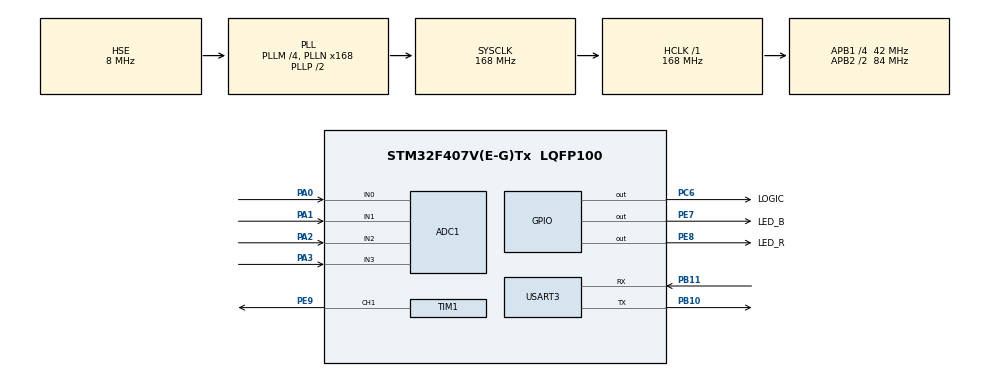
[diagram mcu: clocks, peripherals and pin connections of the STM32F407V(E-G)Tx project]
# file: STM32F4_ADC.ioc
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ADC1.Channel-0\#ChannelRegularConversion=ADC_CHANNEL_0
ADC1.ContinuousConvMode=ENABLE
ADC1.DMAContinuousRequests=ENABLE
ADC1.NbrOfConversionFlag=1
ADC1.Rank-0\#ChannelRegularConversion=1
ADC1.SamplingTime-0\#ChannelRegularConversion=ADC_SAMPLETIME_3CYCLES
ADC1.ScanConvMode=DISABLE
ADC1.master=1
Dma.ADC1.0.Direction=DMA_PERIPH_TO_MEMORY
Dma.ADC1.0.FIFOMode=DMA_FIFOMODE_DISABLE
Dma.ADC1.0.Instance=DMA2_Stream0
Dma.ADC1.0.MemDataAlignment=DMA_MDATAALIGN_HALFWORD
Dma.ADC1.0.MemInc=DMA_MINC_ENABLE
Dma.ADC1.0.Mode=DMA_NORMAL
Dma.ADC1.0.PeriphDataAlignment=DMA_PDATAALIGN_HALFWORD
Dma.ADC1.0.PeriphInc=DMA_PINC_DISABLE
Dma.ADC1.0.Priority=DMA_PRIORITY_HIGH
Dma.Request0=ADC1
Mcu.Family=STM32F4
Mcu.Name=STM32F407V(E-G)Tx
Mcu.Package=LQFP100
NVIC.ADC_IRQn=true\:0\:0\:false\:false\:true\:true\:true\:true
NVIC.DMA2_Stream0_IRQn=true\:0\:0\:false\:false\:true\:false\:true\:true
NVIC.PriorityGroup=NVIC_PRIORITYGROUP_4
PA0-WKUP.Signal=ADCx_IN0
PA1.Signal=ADCx_IN1
PA13.Mode=Serial_Wire
PA13.Signal=SYS_JTMS-SWDIO
PA14.Mode=Serial_Wire
PA14.Signal=SYS_JTCK-SWCLK
PA2.Signal=ADCx_IN2
PA3.Signal=ADCx_IN3
PB10.Mode=Asynchronous
PB10.Signal=USART3_TX
PB11.Mode=Asynchronous
PB11.Signal=USART3_RX
PC14-OSC32_IN.Mode=LSE-External-Oscillator
PC14-OSC32_IN.Signal=RCC_OSC32_IN
PC15-OSC32_OUT.Mode=LSE-External-Oscillator
PC15-OSC32_OUT.Signal=RCC_OSC32_OUT
PC6.GPIO_Label=LOGIC
PC6.GPIO_PuPd=GPIO_PULLUP
PC6.GPIO_Speed=GPIO_SPEED_FREQ_VERY_HIGH
PC6.Signal=GPIO_Output
PE7.GPIO_Label=LED_B
PE7.GPIO_ModeDefaultOutputPP=GPIO_MODE_OUTPUT_PP
PE7.GPIO_Speed=GPIO_SPEED_FREQ_MEDIUM
PE7.PinState=GPIO_PIN_RESET
PE7.Signal=GPIO_Output
PE8.GPIO_Label=LED_R
PE8.GPIO_ModeDefaultOutputPP=GPIO_MODE_OUTPUT_PP
PE8.GPIO_Speed=GPIO_SPEED_FREQ_MEDIUM
PE8.PinState=GPIO_PIN_RESET
PE8.Signal=GPIO_Output
PE9.Signal=S_TIM1_CH1
PH0-OSC_IN.Mode=HSE-External-Oscillator
PH0-OSC_IN.Signal=RCC_OSC_IN
PH1-OSC_OUT.Mode=HSE-External-Oscillator
PH1-OSC_OUT.Signal=RCC_OSC_OUT
ProjectManager.HeapSize=0x200
ProjectManager.StackSize=0x400
ProjectManager.TargetToolchain=MDK-ARM V5.32
RCC.48MHZClocksFreq_Value=84000000
RCC.AHBFreq_Value=168000000
RCC.APB1CLKDivider=RCC_HCLK_DIV4
RCC.APB1Freq_Value=42000000
RCC.APB1TimFreq_Value=84000000
RCC.APB2CLKDivider=RCC_HCLK_DIV2
RCC.APB2Freq_Value=84000000
RCC.APB2TimFreq_Value=168000000
RCC.CortexFreq_Value=168000000
RCC.HCLKFreq_Value=168000000
RCC.HSE_VALUE=8000000
RCC.HSI_VALUE=16000000
RCC.PLLM=4
RCC.PLLN=168
RCC.PLLSourceVirtual=RCC_PLLSOURCE_HSE
RCC.SYSCLKFreq_VALUE=168000000
RCC.SYSCLKSource=RCC_SYSCLKSOURCE_PLLCLK
RCC.VCOOutputFreq_Value=336000000
SH.ADCx_IN0.0=ADC1_IN0,IN0
SH.ADCx_IN1.0=ADC1_IN1,IN1
SH.ADCx_IN2.0=ADC1_IN2,IN2
SH.ADCx_IN3.0=ADC1_IN3,IN3
SH.S_TIM1_CH1.0=TIM1_CH1,PWM Generation1 CH1
TIM1.Channel-PWM\ Generation1\ CH1=TIM_CHANNEL_1
TIM1.Period=100
TIM1.Prescaler=839
TIM1.Pulse-PWM\ Generation1\ CH1=50
USART3.VirtualMode=VM_ASYNC
VP_TIM1_VS_ClockSourceINT.Mode=Internal
board=custom

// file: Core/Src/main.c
/* USER CODE BEGIN Header */
/**
  ******************************************************************************
  * @file           : main.c
  * @brief          : Main program body
  ******************************************************************************
  * @attention
  *
  * Copyright (c) 2025 STMicroelectronics.
  * All rights reserved.
  *
  * This software is licensed under terms that can be found in the LICENSE file
  * in the root directory of this software component.
  * If no LICENSE file comes with this software, it is provided AS-IS.
  *
  ******************************************************************************
  */
/* USER CODE END Header */
#include "main.h"
#include "adc.h"
#include "dma.h"
#include "tim.h"
#include "usart.h"
#include "gpio.h"

/* USER CODE BEGIN Includes */
#include "myapp.h"
/* USER CODE END Includes */

void SystemClock_Config(void);

int main(void)
{

  /* MCU Configuration--------------------------------------------------------*/

  /* Reset of all peripherals, Initializes the Flash interface and the Systick. */
  HAL_Init();

  /* Configure the system clock */
  SystemClock_Config();

  /* Initialize all configured peripherals */
  MX_GPIO_Init();
  MX_DMA_Init();
  MX_USART3_UART_Init();
  MX_ADC1_Init();
  MX_TIM1_Init();
  /* USER CODE BEGIN 2 */
  MyApp();
  /* USER CODE END 2 */

  /* Infinite loop */
  while (1)
  {

  }
}

void SystemClock_Config(void)
{
  RCC_OscInitTypeDef RCC_OscInitStruct = {0};
  RCC_ClkInitTypeDef RCC_ClkInitStruct = {0};

  /** Configure the main internal regulator output voltage
  */
  __HAL_RCC_PWR_CLK_ENABLE();
  __HAL_PWR_VOLTAGESCALING_CONFIG(PWR_REGULATOR_VOLTAGE_SCALE1);

  /** Initializes the RCC Oscillators according to the specified parameters
  * in the RCC_OscInitTypeDef structure.
  */
  RCC_OscInitStruct.OscillatorType = RCC_OSCILLATORTYPE_HSE;
  RCC_OscInitStruct.HSEState = RCC_HSE_ON;
  RCC_OscInitStruct.PLL.PLLState = RCC_PLL_ON;
  RCC_OscInitStruct.PLL.PLLSource = RCC_PLLSOURCE_HSE;
  RCC_OscInitStruct.PLL.PLLM = 4;
  RCC_OscInitStruct.PLL.PLLN = 168;
  RCC_OscInitStruct.PLL.PLLP = RCC_PLLP_DIV2;
  RCC_OscInitStruct.PLL.PLLQ = 4;
  if (HAL_RCC_OscConfig(&RCC_OscInitStruct) != HAL_OK)
  {
    Error_Handler();
  }

  /** Initializes the CPU, AHB and APB buses clocks
  */
  RCC_ClkInitStruct.ClockType = RCC_CLOCKTYPE_HCLK|RCC_CLOCKTYPE_SYSCLK
                              |RCC_CLOCKTYPE_PCLK1|RCC_CLOCKTYPE_PCLK2;
  RCC_ClkInitStruct.SYSCLKSource = RCC_SYSCLKSOURCE_PLLCLK;
  RCC_ClkInitStruct.AHBCLKDivider = RCC_SYSCLK_DIV1;
  RCC_ClkInitStruct.APB1CLKDivider = RCC_HCLK_DIV4;
  RCC_ClkInitStruct.APB2CLKDivider = RCC_HCLK_DIV2;

  if (HAL_RCC_ClockConfig(&RCC_ClkInitStruct, FLASH_LATENCY_5) != HAL_OK)
  {
    Error_Handler();
  }
}

void Error_Handler(void)
{
  __disable_irq();
  while (1)
  {
  }
}
